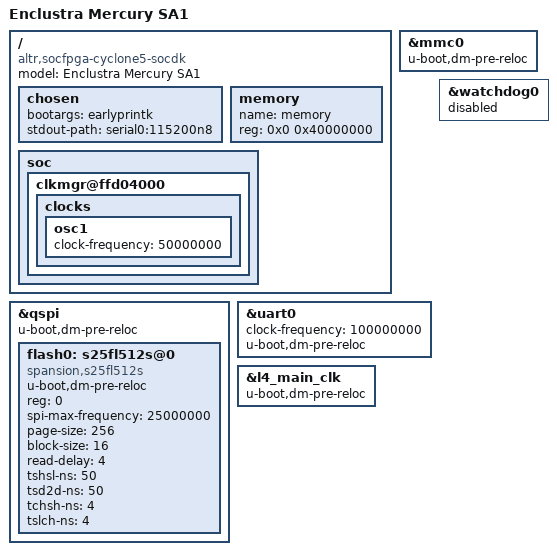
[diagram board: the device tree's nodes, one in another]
/dts-v1/;
#include "socfpga_cyclone5.dtsi"
#include "socfpga-common-u-boot.dtsi"

/ {
	model = "Enclustra Mercury SA1";
	compatible = "altr,socfpga-cyclone5-socdk", "altr,socfpga-cyclone5", "altr,socfpga";

	chosen {
		bootargs = "earlyprintk";
		stdout-path = "serial0:115200n8";
	};

	memory {
		name = "memory";
		device_type = "memory";
		reg = <0x0 0x40000000>; /* 1GB */
	};

	soc {
		clkmgr@ffd04000 {
			clocks {
				osc1 {
					clock-frequency = <50000000>;
				};
			};
		};
	};
};

&mmc0 {
	u-boot,dm-pre-reloc;
	status = "okay";
};

&qspi {
	u-boot,dm-pre-reloc;
	status = "okay";

	flash0: s25fl512s@0 {
		u-boot,dm-pre-reloc;
		#address-cells = <1>;
		#size-cells = <1>;
		compatible = "spansion,s25fl512s", "jedec,spi-nor";
		reg = <0>;
		spi-max-frequency = <25000000>;

		page-size = <256>;
		block-size = <16>; /* 2^16, 64KB */
		read-delay = <4>;
		tshsl-ns = <50>;
		tsd2d-ns = <50>;
		tchsh-ns = <4>;
		tslch-ns = <4>;
	};
};

&uart0 {
	clock-frequency = <100000000>;
	u-boot,dm-pre-reloc;
};

&l4_main_clk {
	u-boot,dm-pre-reloc;
};

&watchdog0 {
	status = "disabled";
};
